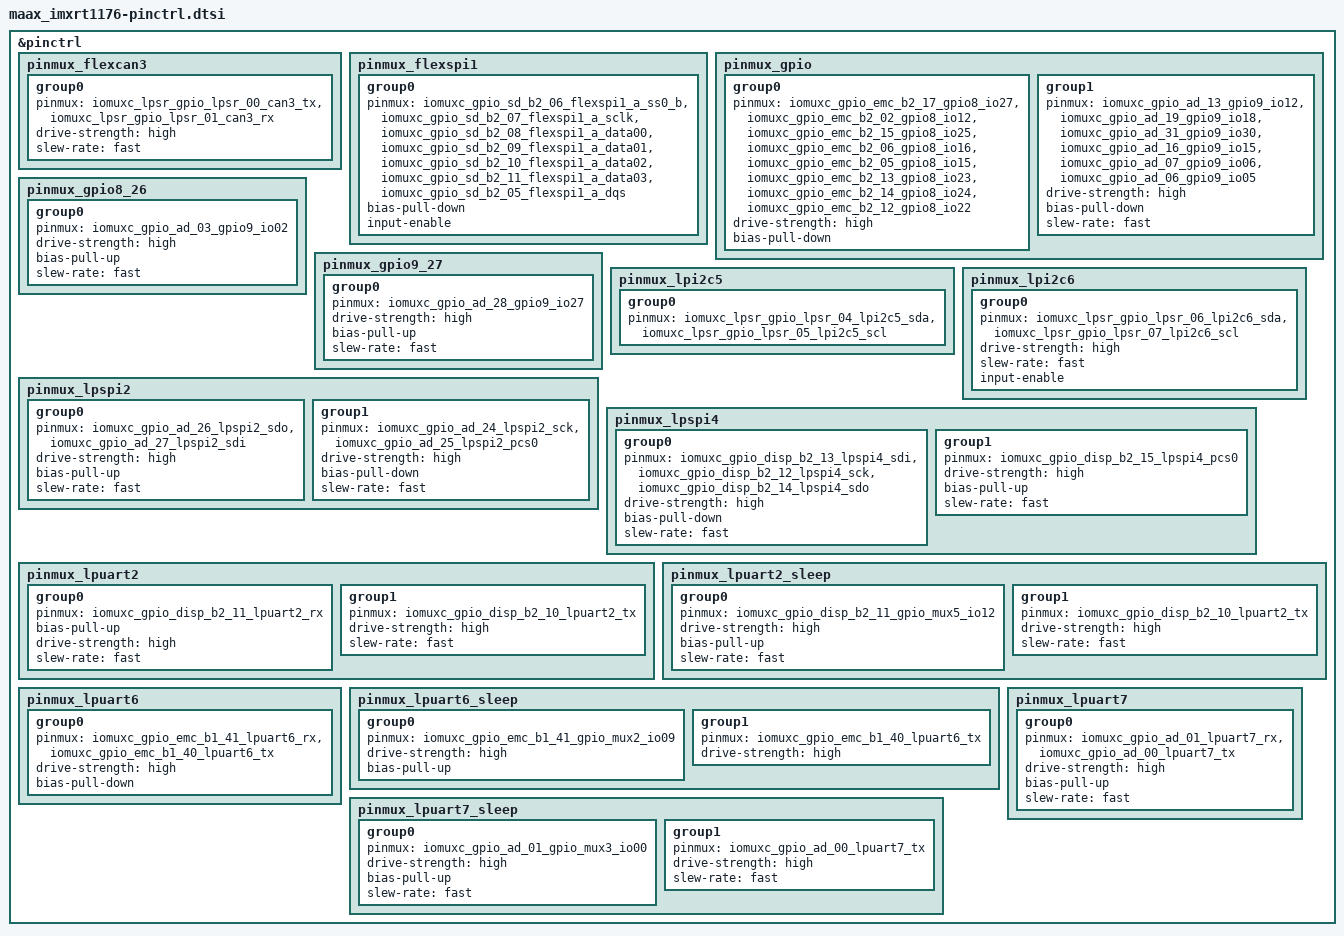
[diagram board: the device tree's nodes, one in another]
/*
 * Copyright 2026 NXP
 * All rights reserved.
 *
 * SPDX-License-Identifier: BSD-3-Clause
 */

/***********************************************************************************************************************
 * This file was generated by the MCUXpresso Config Tools. Any manual edits made to this file
 * will be overwritten if the respective MCUXpresso Config Tools is used to update this file.
 **********************************************************************************************************************/

#include <nxp/nxp_imx/rt/mimxrt1176dvmaa-pinctrl.dtsi>

&pinctrl {

	/* Configures pin routing and optionally pin electrical features. */
	pinmux_flexcan3: pinmux_flexcan3 {
		group0 {
			pinmux = <&iomuxc_lpsr_gpio_lpsr_00_can3_tx>,
				<&iomuxc_lpsr_gpio_lpsr_01_can3_rx>;
			drive-strength = "high";
			slew-rate = "fast";
		};
	};

	/* Configures pin routing and optionally pin electrical features. */
	pinmux_flexspi1: pinmux_flexspi1 {
		group0 {
			pinmux = <&iomuxc_gpio_sd_b2_06_flexspi1_a_ss0_b>,
				<&iomuxc_gpio_sd_b2_07_flexspi1_a_sclk>,
				<&iomuxc_gpio_sd_b2_08_flexspi1_a_data00>,
				<&iomuxc_gpio_sd_b2_09_flexspi1_a_data01>,
				<&iomuxc_gpio_sd_b2_10_flexspi1_a_data02>,
				<&iomuxc_gpio_sd_b2_11_flexspi1_a_data03>,
				<&iomuxc_gpio_sd_b2_05_flexspi1_a_dqs>;
			bias-pull-down;
			input-enable;
		};
	};

	/* Configures pin routing and optionally pin electrical features. */
	pinmux_gpio: pinmux_gpio {
		group0 {
			pinmux = <&iomuxc_gpio_emc_b2_17_gpio8_io27>,
				<&iomuxc_gpio_emc_b2_02_gpio8_io12>,
				<&iomuxc_gpio_emc_b2_15_gpio8_io25>,
				<&iomuxc_gpio_emc_b2_06_gpio8_io16>,
				<&iomuxc_gpio_emc_b2_05_gpio8_io15>,
				<&iomuxc_gpio_emc_b2_13_gpio8_io23>,
				<&iomuxc_gpio_emc_b2_14_gpio8_io24>,
				<&iomuxc_gpio_emc_b2_12_gpio8_io22>;
			drive-strength = "high";
			bias-pull-down;
		};
		group1 {
			pinmux = <&iomuxc_gpio_ad_13_gpio9_io12>,
				<&iomuxc_gpio_ad_19_gpio9_io18>,
				<&iomuxc_gpio_ad_31_gpio9_io30>,
				<&iomuxc_gpio_ad_16_gpio9_io15>,
				<&iomuxc_gpio_ad_07_gpio9_io06>,
				<&iomuxc_gpio_ad_06_gpio9_io05>;
			drive-strength = "high";
			bias-pull-down;
			slew-rate = "fast";
		};
	};

	/* Configures pin routing and optionally pin electrical features. */
	pinmux_gpio8_26: pinmux_gpio8_26 {
		group0 {
			pinmux = <&iomuxc_gpio_ad_03_gpio9_io02>;
			drive-strength = "high";
			bias-pull-up;
			slew-rate = "fast";
		};
	};

	/* Configures pin routing and optionally pin electrical features. */
	pinmux_gpio9_27: pinmux_gpio9_27 {
		group0 {
			pinmux = <&iomuxc_gpio_ad_28_gpio9_io27>;
			drive-strength = "high";
			bias-pull-up;
			slew-rate = "fast";
		};
	};

	/* Configures pin routing and optionally pin electrical features. */
	pinmux_lpi2c5: pinmux_lpi2c5 {
		group0 {
			pinmux = <&iomuxc_lpsr_gpio_lpsr_04_lpi2c5_sda>,
				<&iomuxc_lpsr_gpio_lpsr_05_lpi2c5_scl>;

		};
	};

	/* Configures pin routing and optionally pin electrical features. */
	pinmux_lpi2c6: pinmux_lpi2c6 {
		group0 {
			pinmux = <&iomuxc_lpsr_gpio_lpsr_06_lpi2c6_sda>,
				<&iomuxc_lpsr_gpio_lpsr_07_lpi2c6_scl>;
			drive-strength = "high";
			slew-rate = "fast";
			input-enable;
		};
	};

	/* Configures pin routing and optionally pin electrical features. */
	pinmux_lpspi2: pinmux_lpspi2 {
		group0 {
			pinmux = <&iomuxc_gpio_ad_26_lpspi2_sdo>,
				<&iomuxc_gpio_ad_27_lpspi2_sdi>;
			drive-strength = "high";
			bias-pull-up;
			slew-rate = "fast";
		};
		group1 {
			pinmux = <&iomuxc_gpio_ad_24_lpspi2_sck>,
				<&iomuxc_gpio_ad_25_lpspi2_pcs0>;
			drive-strength = "high";
			bias-pull-down;
			slew-rate = "fast";
		};
	};

	/* Configures pin routing and optionally pin electrical features. */
	pinmux_lpspi4: pinmux_lpspi4 {
		group0 {
			pinmux = <&iomuxc_gpio_disp_b2_13_lpspi4_sdi>,
				<&iomuxc_gpio_disp_b2_12_lpspi4_sck>,
				<&iomuxc_gpio_disp_b2_14_lpspi4_sdo>;
			drive-strength = "high";
			bias-pull-down;
			slew-rate = "fast";
		};
		group1 {
			pinmux = <&iomuxc_gpio_disp_b2_15_lpspi4_pcs0>;
			drive-strength = "high";
			bias-pull-up;
			slew-rate = "fast";
		};
	};

	/* Configures pin routing and optionally pin electrical features. */
	pinmux_lpuart2: pinmux_lpuart2 {
		group0 {
			pinmux = <&iomuxc_gpio_disp_b2_11_lpuart2_rx>;
			bias-pull-up;
			drive-strength = "high";
			slew-rate = "fast";
		};

		group1 {
			pinmux = <&iomuxc_gpio_disp_b2_10_lpuart2_tx>;
			drive-strength = "high";
			slew-rate = "fast";
		};
	};

	/* Configures pin routing and optionally pin electrical features. */
	pinmux_lpuart2_sleep: pinmux_lpuart2_sleep {
		group0 {
			pinmux = <&iomuxc_gpio_disp_b2_11_gpio_mux5_io12>;
			drive-strength = "high";
			bias-pull-up;
			slew-rate = "fast";
		};
		group1 {
			pinmux = <&iomuxc_gpio_disp_b2_10_lpuart2_tx>;
			drive-strength = "high";
			slew-rate = "fast";
		};
	};

	/* Configures pin routing and optionally pin electrical features. */
	pinmux_lpuart6: pinmux_lpuart6 {
		group0 {
			pinmux = <&iomuxc_gpio_emc_b1_41_lpuart6_rx>,
				<&iomuxc_gpio_emc_b1_40_lpuart6_tx>;
			drive-strength = "high";
			bias-pull-down;
		};
	};

	/* Configures pin routing and optionally pin electrical features. */
	pinmux_lpuart6_sleep: pinmux_lpuart6_sleep {
		group0 {
			pinmux = <&iomuxc_gpio_emc_b1_41_gpio_mux2_io09>;
			drive-strength = "high";
			bias-pull-up;
		};
		group1 {
			pinmux = <&iomuxc_gpio_emc_b1_40_lpuart6_tx>;
			drive-strength = "high";
		};
	};

	/* Configures pin routing and optionally pin electrical features. */
	pinmux_lpuart7: pinmux_lpuart7 {
		group0 {
			pinmux = <&iomuxc_gpio_ad_01_lpuart7_rx>,
				<&iomuxc_gpio_ad_00_lpuart7_tx>;
			drive-strength = "high";
			bias-pull-up;
			slew-rate = "fast";
		};
	};

	/* Configures pin routing and optionally pin electrical features. */
	pinmux_lpuart7_sleep: pinmux_lpuart7_sleep {
		group0 {
			pinmux = <&iomuxc_gpio_ad_01_gpio_mux3_io00>;
			drive-strength = "high";
			bias-pull-up;
			slew-rate = "fast";
		};
		group1 {
			pinmux = <&iomuxc_gpio_ad_00_lpuart7_tx>;
			drive-strength = "high";
			slew-rate = "fast";
		};
	};


};
